# max32570 register map
Vendor: Maxim-Integrated; Series: ARMCM4; File version: 1.0
CPU: CM4 r2p1, little endian, MPU, FPU, 3 interrupt priority bits
Registers are 32-bit, read-write, reset 0x0 unless marked. A register's access mark holds for its fields unless they carry their own. Offsets are from the block's base; [hi:lo] are bit positions; {n}, {i} and the like mark numbered series.

## SIR — System Initialization Registers.
Base 0x40000400
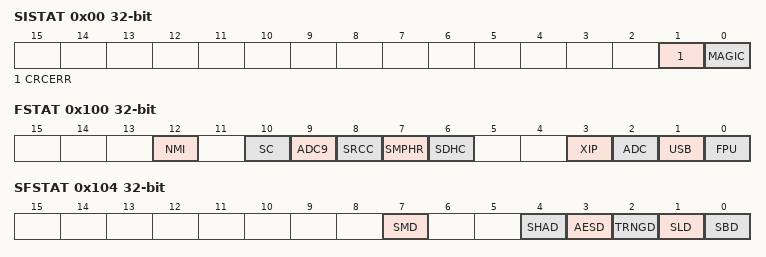
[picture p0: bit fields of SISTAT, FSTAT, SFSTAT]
0x00 SISTAT ro — System Initialization Status Register.
  [1] CRCERR — CRC Error Status. This bit is set by the system initialization block following power-up.
    on read: 0=noError (No CRC errors occurred during the read of the OTP memory block.); 1=error (A CRC error occurred while reading the OTP. The address of the failure location in the OTP memory is stored in the ERRADDR register.)
  [0] MAGIC — Magic Word Validation. This bit is set by the system initialization block following power-up.
    on read: 0=magicNotSet (Magic word was not set (OTP has not been initialized properly).); 1=magicSet (Magic word was set (OTP contains valid settings).)
0x04 ERRADDR ro — Read-only field set by the SIB block if a CRC error occurs during the read of the OTP memory. Contains the failing address in OTP memory (when CRCERR equals 1).
0x100 FSTAT ro — funcstat register.
  [all] fields
    0=no; 1=yes
  [12] NMI — NMI function.
  [10] SC — SC function.
  [9] ADC9 — ADC9 function.
  [8] SRCC — SRCC function.
  [7] SMPHR — SMPHR function.
  [6] SDHC — SDHC function.
  [3] XIP — XiP function.
  [2] ADC — 10-bit Sigma Delta ADC.
  [1] USB — USB Device.
  [0] FPU — FPU Function.
0x104 SFSTAT ro — secfuncstat register.
  [all] fields
    0=no; 1=yes
  [7] SMD — SMD function.
  [4] SHAD — SHA function.
  [3] AESD — AES function.
  [2] TRNGD — TRNG function.
  [1] SLD — SLD function.
  [0] SBD — SBD function.

## SKBD — Secure Keyboard
Base 0x40032000
0x00 CR0 — Input Output Select Bits. Each bit of IOSEL selects the pin direction for the corresponding KBDIO pin. If IOSEL[0] = 1, KBDIO0 is an output.
  [9:0] KBDIO_0 — Input Output Select for KBDIO0 pin.
    0=input; 1=output
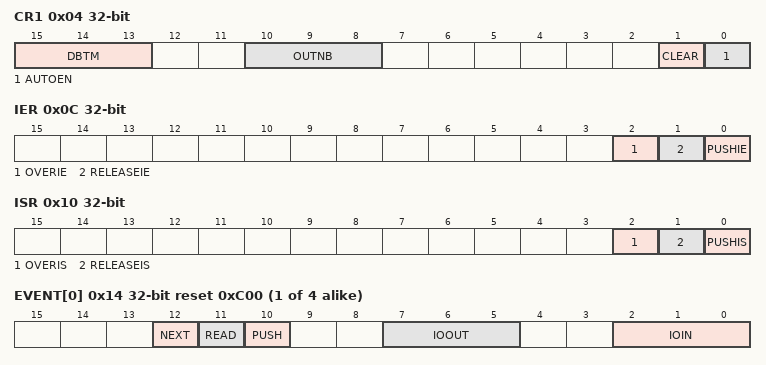
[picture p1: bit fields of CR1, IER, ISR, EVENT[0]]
0x04 CR1 — Control Register 1
  [15:13] DBTM — Debounce Time. Number of milliseconds a keypress event must be active before it is considered actual. NOTE: Debounce time values based on system running from an external 12MHz clock source with PLL0 enabled. Other external crystal values will cause the debounce time to scale linearly.
    0=time4ms (4.1 ms); 1=time5ms (5.3 ms); 2=time6ms (6.5 ms); 3=time7ms (7.6 ms); 4=time8ms (8.8 ms); 5=time10ms (10.0 ms); 6=time11ms (11.2 ms); 7=time12ms (12.3 ms)
  [10:8] OUTNB — Output Number. Number of KBDIO pins selected as outputs. NOTE: Output pins must be allocated contiguously starting with KBDIO0 and continuing through to KBDIO7.
  [1] CLEAR — Auto Clear Bit
    0=disable; 1=enable
  [0] AUTOEN — Automatic Keyboard Scan Enable
    0=disable; 1=enable
0x08 SR ro — Status Register
  [0] BUSY — Busy bit. This bit is set by hardware when the automatic keyboard scan is enabled and running. This bit is clear at all other times.
    0=idle; 1=busy
0x0C IER — Interrupt Enable Register
  [all] fields
    0=disable; 1=enable
  [2] OVERIE — Overrun Event Enable Bit. When set, this bit enables an interrupt to be generated on an overrun event. Automatic keyboard scan must be enabled.
  [1] RELEASEIE — Release Event Enable Bit. When set, this bit enables an interrupt to be generated on a key release event. Automatic keyboard scan must be enabled.
  [0] PUSHIE — Push Event Enable Bit. When set, this bit enables an interrupt to be generated on a key push event. Automatic keyboard scan must be enabled.
0x10 ISR — Interrupt Status Register
  [all] fields
    0=inactive (No interrupt is pending.); 1=pending (An interrupt is pending.)
  [2] OVERIS — Overrun Event Enable Bit. This bit is set by hardware when an overrun event has occurred. If the interrupt is enabled for this flag, a system interrupt will be fired. If the interrupt enable is not set, the flag will be set, but no interrupt will fire. This bit must be cleared by software.
  [1] RELEASEIS — Release Interrupt Flag. This bit is set by hardware when a key has been released. If the interrupt is enabled for this flag, a system interrupt will be fired. If the interrupt enable is not set, the flag will be set, but no interrupt will fire. This bit must be cleared by software.
  [0] PUSHIS — Push Interrupt Flag. This bit is set by hardware when a key has been pushed. If the interrupt is enabled for this flag, a system interrupt will be fired. If the interrupt enable is not set, the flag will be set, but no interrupt will fire. This bit must be cleared by software.
{0x14+4i} EVENT[{i}] (i=0..3) ro reset 0xC00 — Key Register
  [12] NEXT — If set to 1 one of the next key registers (x+1 to 3) contains a key event.
    0=none (No more key register contain a key event.); 1=more (Other key registers contain a key event.)
  [11] READ — If set to 1 this register has been read. If set to 0 the key register has not been read since its last change.
    0=notRead (This register has not been read since its last change.); 1=read (This register has been read.)
  [10] PUSH — If set to 1 the key has been released. If set to 0 the key has been pushed.
    0=pushed; 1=released
  [7:5] IOOUT — IO Output. Output pin of key event.
  [2:0] IOIN — IO Input. Input pin of key event.
